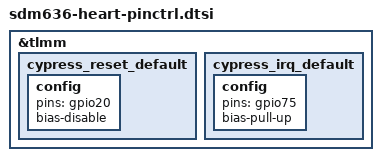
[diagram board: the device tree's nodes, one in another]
/* Copyright (c) 2017, Motorola Mobility Inc. All rights reserved.
 *
 * This program is free software; you can redistribute it and/or modify
 * it under the terms of the GNU General Public License version 2 and
 * only version 2 as published by the Free Software Foundation.
 *
 * This program is distributed in the hope that it will be useful,
 * but WITHOUT ANY WARRANTY; without even the implied warranty of
 * MERCHANTABILITY or FITNESS FOR A PARTICULAR PURPOSE.  See the
 * GNU General Public License for more details.
 */

&tlmm {
	cypress_reset_default: cypress_reset_default {
		config {
			pins = "gpio20";
			bias-disable;
		};
	};
	cypress_irq_default: cypress_irq_default {
		config {
			pins = "gpio75";
			bias-pull-up;
		};
	};
};
